# STM32L422 register map
File version: 1.0
CPU: CM4 r0p1, little endian, MPU, FPU, 4 interrupt priority bits
Registers are 32-bit, read-write, reset 0x0 unless marked. A register's access mark holds for its fields unless they carry their own. Offsets are from the block's base; [hi:lo] are bit positions; lines under a group give offsets from that group; {n}, {i} and the like mark numbered series; 'fields as' and 'values as' point back to an identical list.

## TSC — Touch sensing controller
Base 0x40024000
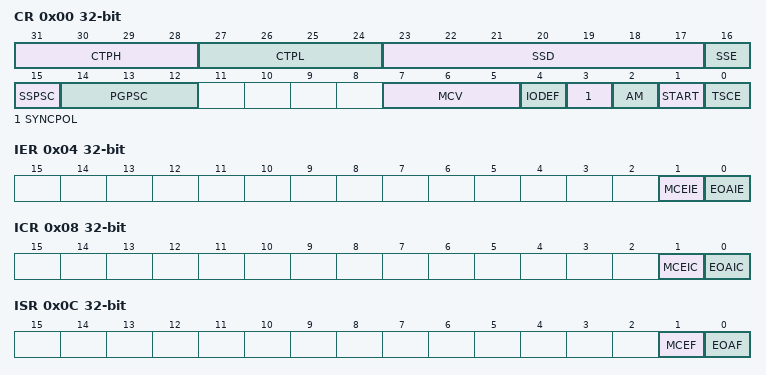
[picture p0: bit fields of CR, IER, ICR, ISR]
0x00 CR — control register
  [31:28] CTPH — Charge transfer pulse high
  [27:24] CTPL — Charge transfer pulse low
  [23:17] SSD — Spread spectrum deviation
  [16] SSE — Spread spectrum enable
  [15] SSPSC — Spread spectrum prescaler
  [14:12] PGPSC — pulse generator prescaler
  [7:5] MCV — Max count value
  [4] IODEF — I/O Default mode
  [3] SYNCPOL — Synchronization pin polarity
  [2] AM — Acquisition mode
  [1] START — Start a new acquisition
  [0] TSCE — Touch sensing controller enable
0x04 IER — interrupt enable register
  [1] MCEIE — Max count error interrupt enable
  [0] EOAIE — End of acquisition interrupt enable
0x08 ICR — interrupt clear register
  [1] MCEIC — Max count error interrupt clear
  [0] EOAIC — End of acquisition interrupt clear
0x0C ISR — interrupt status register
  [1] MCEF — Max count error flag
  [0] EOAF — End of acquisition flag
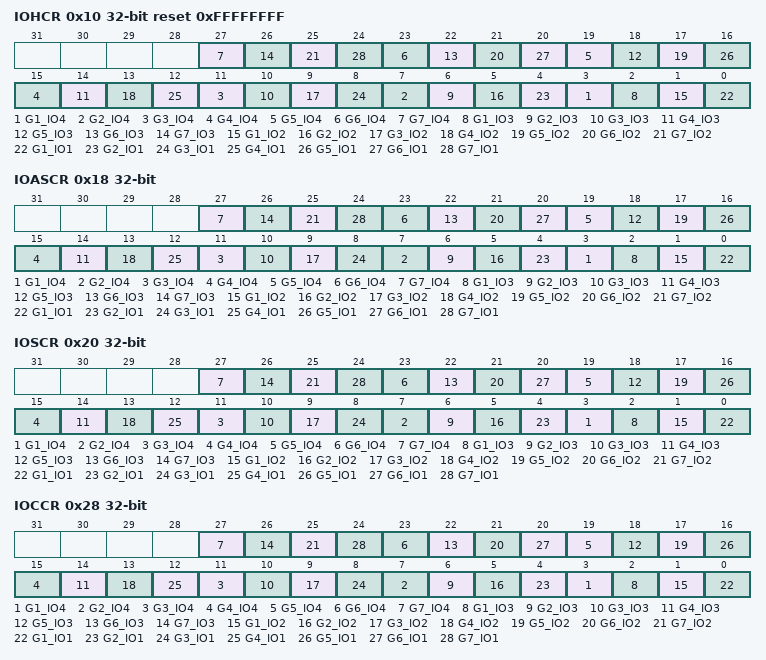
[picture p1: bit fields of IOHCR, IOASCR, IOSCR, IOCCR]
0x10 IOHCR reset 0xFFFFFFFF — I/O hysteresis control register
  [4n-1] G{n}_IO4 (n=1..7), [4n-2] G{n}_IO3 (n=1..7), [4n-3] G{n}_IO2 (n=1..7), [4n-4] G{n}_IO1 (n=1..7)
0x18 IOASCR — I/O analog switch control register
  fields as IOHCR
0x20 IOSCR — I/O sampling control register
  fields as IOHCR
0x28 IOCCR — I/O channel control register
  fields as IOHCR
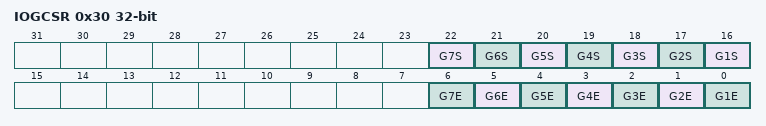
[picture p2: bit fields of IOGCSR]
0x30 IOGCSR access per field — I/O group control status register
  [n+15] G{n}S ro (n=1..7) — Analog I/O group x status
  [n-1] G{n}E rw (n=1..7) — Analog I/O group x enable
{0x30+4i} IOG{i}CR ro (i=1..8) — I/O group x counter register
  [13:0] CNT — Counter value

## WWDG — System window watchdog
Base 0x40002C00
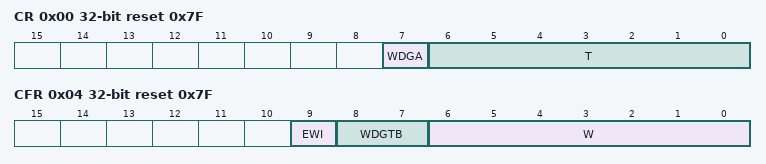
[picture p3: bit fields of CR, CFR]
0x00 CR reset 0x7F — Control register
  [7] WDGA — Activation bit
  [6:0] T — 7-bit counter (MSB to LSB)
0x04 CFR reset 0x7F — Configuration register
  [9] EWI — Early wakeup interrupt
  [8:7] WDGTB — Timer base
  [6:0] W — 7-bit window value
0x08 SR — Status register
  [0] EWIF — Early wakeup interrupt flag

## QUADSPI — QuadSPI interface
Base 0xA0001000
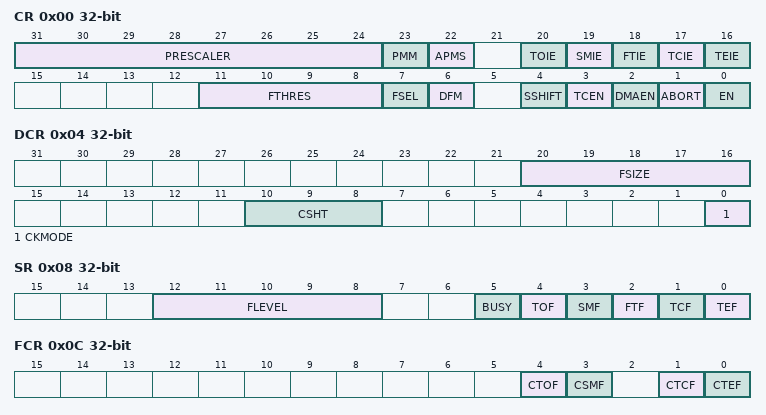
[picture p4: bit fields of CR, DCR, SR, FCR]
0x00 CR — control register
  [31:24] PRESCALER — Clock prescaler
  [23] PMM — Polling match mode
  [22] APMS — Automatic poll mode stop
  [20] TOIE — TimeOut interrupt enable
  [19] SMIE — Status match interrupt enable
  [18] FTIE — FIFO threshold interrupt enable
  [17] TCIE — Transfer complete interrupt enable
  [16] TEIE — Transfer error interrupt enable
  [11:8] FTHRES — FIFO threshold level
  [7] FSEL — Flash memory selection
  [6] DFM — Dual-flash mode
  [4] SSHIFT — Sample shift
  [3] TCEN — Timeout counter enable
  [2] DMAEN — DMA enable
  [1] ABORT — Abort request
  [0] EN — Enable
0x04 DCR — device configuration register
  [20:16] FSIZE — FLASH memory size
  [10:8] CSHT — Chip select high time
  [0] CKMODE — Mode 0 / mode 3
0x08 SR ro — status register
  [12:8] FLEVEL — FIFO level
  [5] BUSY
  [4] TOF — Timeout flag
  [3] SMF — Status match flag
  [2] FTF — FIFO threshold flag
  [1] TCF — Transfer complete flag
  [0] TEF — Transfer error flag
0x0C FCR — flag clear register
  [4] CTOF — Clear timeout flag
  [3] CSMF — Clear status match flag
  [1] CTCF — Clear transfer complete flag
  [0] CTEF — Clear transfer error flag
0x10 DLR — data length register
  [31:0] DL — Data length
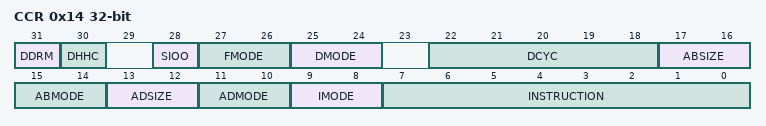
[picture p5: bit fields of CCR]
0x14 CCR — communication configuration register
  [31] DDRM — Double data rate mode
  [30] DHHC — DDR hold
  [28] SIOO — Send instruction only once mode
  [27:26] FMODE — Functional mode
  [25:24] DMODE — Data mode
  [22:18] DCYC — Number of dummy cycles
  [17:16] ABSIZE — Alternate bytes size
  [15:14] ABMODE — Alternate bytes mode
  [13:12] ADSIZE — Address size
  [11:10] ADMODE — Address mode
  [9:8] IMODE — Instruction mode
  [7:0] INSTRUCTION
0x18 AR — address register
  [31:0] ADDRESS
0x1C ABR
  [31:0] ALTERNATE
0x20 DR — data register
  [31:0] DATA
0x24 PSMKR — polling status mask register
  [31:0] MASK — Status mask
0x28 PSMAR — polling status match register
  [31:0] MATCH — Status match
0x2C PIR — polling interval register
  [15:0] INTERVAL — Polling interval
0x30 LPTR — low-power timeout register
  [15:0] TIMEOUT — Timeout period

## GPIOA — General-purpose I/Os
Base 0x48000000
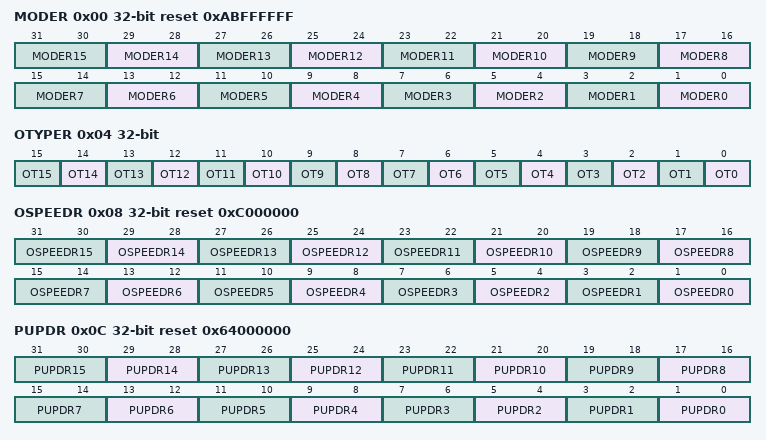
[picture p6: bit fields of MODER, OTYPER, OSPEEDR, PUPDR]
0x00 MODER reset 0xABFFFFFF — GPIO port mode register
  [2n+1:2n] MODER{n} (n=0..15) — Port x configuration bits (y = 0..15)
0x04 OTYPER — GPIO port output type register
  [n] OT{n} (n=0..15) — Port x configuration bits (y = 0..15)
0x08 OSPEEDR reset 0xC000000 — GPIO port output speed register
  [2n+1:2n] OSPEEDR{n} (n=0..15) — Port x configuration bits (y = 0..15)
0x0C PUPDR reset 0x64000000 — GPIO port pull-up/pull-down register
  [2n+1:2n] PUPDR{n} (n=0..15) — Port x configuration bits (y = 0..15)
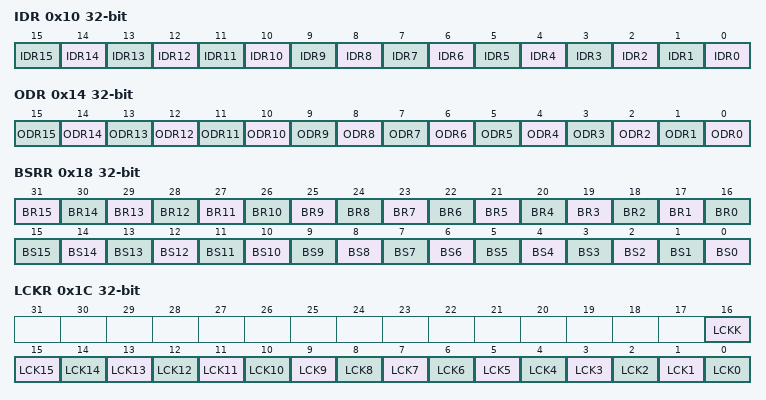
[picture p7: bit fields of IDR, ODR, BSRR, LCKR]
0x10 IDR ro — GPIO port input data register
  [n] IDR{n} (n=0..15) — Port input data (y = 0..15)
0x14 ODR — GPIO port output data register
  [n] ODR{n} (n=0..15) — Port output data (y = 0..15)
0x18 BSRR wo — GPIO port bit set/reset register
  [n+16] BR{n} (n=1..15) — Port x reset bit y (y = 0..15)
  [16] BR0 — Port x set bit y (y= 0..15)
  [n] BS{n} (n=0..15) — Port x set bit y (y= 0..15)
0x1C LCKR — GPIO port configuration lock register
  [16] LCKK — Port x lock bit y (y= 0..15)
  [n] LCK{n} (n=0..15) — Port x lock bit y (y= 0..15)
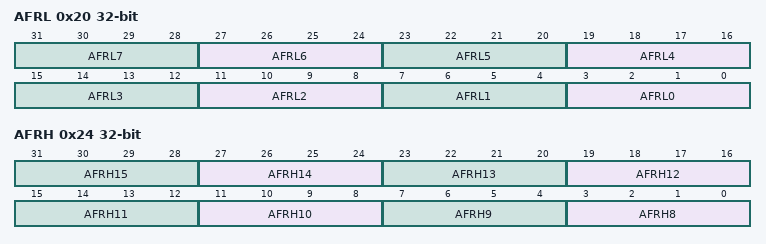
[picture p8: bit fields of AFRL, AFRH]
0x20 AFRL — GPIO alternate function low register
  [4n+3:4n] AFRL{n} (n=0..7) — Alternate function selection for port x bit y (y = 0..7)
0x24 AFRH — GPIO alternate function high register
  [4n-29:4n-32] AFRH{n} (n=8..15) — Alternate function selection for port x bit y (y = 8..15)
0x28 BRR — GPIO port bit reset register

## GPIOB — General-purpose I/Os
Base 0x48000400
Registers as GPIOA; these are added or differ:
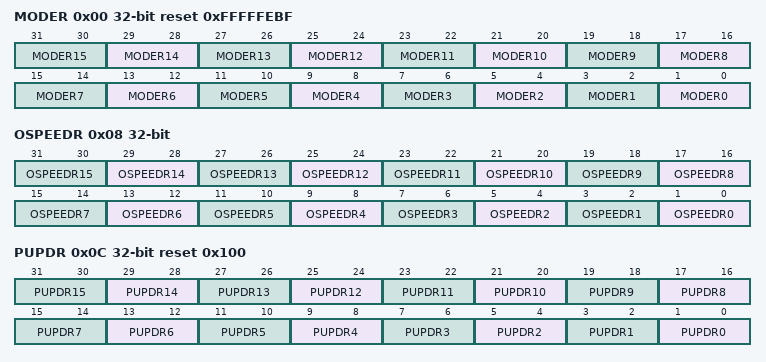
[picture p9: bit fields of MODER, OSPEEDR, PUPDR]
0x00 MODER reset 0xFFFFFEBF — GPIO port mode register
  [2n+1:2n] MODER{n} (n=0..15) — Port x configuration bits (y = 0..15)
0x08 OSPEEDR — GPIO port output speed register
  [2n+1:2n] OSPEEDR{n} (n=0..15) — Port x configuration bits (y = 0..15)
0x0C PUPDR reset 0x100 — GPIO port pull-up/pull-down register
  [2n+1:2n] PUPDR{n} (n=0..15) — Port x configuration bits (y = 0..15)

## GPIOC — General-purpose I/Os
Base 0x48000800
Same registers: GPIOD 0x48000C00
Registers as GPIOB; these are added or differ:
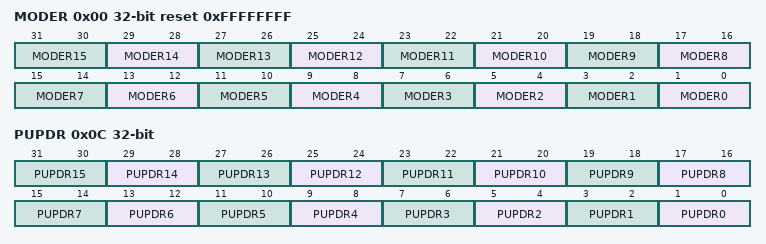
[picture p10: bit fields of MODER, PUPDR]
0x00 MODER reset 0xFFFFFFFF — GPIO port mode register
  [2n+1:2n] MODER{n} (n=0..15) — Port x configuration bits (y = 0..15)
0x0C PUPDR — GPIO port pull-up/pull-down register
  [2n+1:2n] PUPDR{n} (n=0..15) — Port x configuration bits (y = 0..15)

## GPIOH — General-purpose I/Os
Base 0x48001C00
Registers as GPIOC; these are added or differ:
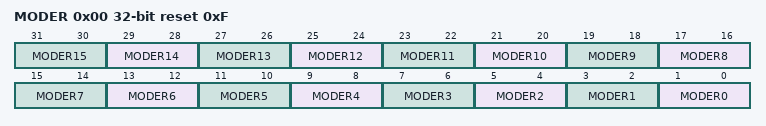
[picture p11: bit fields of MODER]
0x00 MODER reset 0xF — GPIO port mode register
  [2n+1:2n] MODER{n} (n=0..15) — Port x configuration bits (y = 0..15)

## Notices in the file
Copyright (c) 2024 STMicroelectronics.
SPDX-License-Identifier: Apache-2.0
Licensed under the Apache License, Version 2.0 (the "License");
you may not use this file except in compliance with the License.
You may obtain a copy of the License at
http://www.apache.org/licenses/LICENSE-2.0
Unless required by applicable law or agreed to in writing, software
distributed under the License is distributed on an "AS IS" BASIS,
WITHOUT WARRANTIES OR CONDITIONS OF ANY KIND, either express or implied.
See the License for the specific language governing permissions and
limitations under the License.
